# ESP32-H2 register map
Vendor: ESPRESSIF SYSTEMS (SHANGHAI) CO., LTD.; Series: ESP32 H-Series; File version: 12
CPU: RV32IMAC r0p0, little endian, no MPU, no FPU, 0 interrupt priority bits
Address unit: 32 bits
Registers are 32-bit, read-write, reset 0x0 unless marked. A register's access mark holds for its fields unless they carry their own. Offsets are from the block's base; [hi:lo] are bit positions; {n}, {i} and the like mark numbered series.

## GPIO — General Purpose Input/Output
Base 0x60091000
0x00 BT_SELECT — GPIO bit select register
  [31:0] BT_SEL
0x04 OUT — GPIO output register for GPIO0-31
  [31:0] DATA_ORIG
0x08 OUT_W1TS wo — GPIO output set register for GPIO0-31
0x0C OUT_W1TC wo — GPIO output clear register for GPIO0-31
0x1C SDIO_SELECT — GPIO sdio select register
  [7:0] SDIO_SEL
0x20 ENABLE — GPIO output enable register for GPIO0-31
  [31:0] DATA
0x24 ENABLE_W1TS wo — GPIO output enable set register for GPIO0-31
0x28 ENABLE_W1TC wo — GPIO output enable clear register for GPIO0-31
0x38 STRAP ro — pad strapping register
  [15:0] STRAPPING
0x3C IN ro — GPIO input register for GPIO0-31
  [31:0] DATA_NEXT
0x44 STATUS — GPIO interrupt status register for GPIO0-31
  [31:0] INTERRUPT
0x48 STATUS_W1TS wo — GPIO interrupt status set register for GPIO0-31
0x4C STATUS_W1TC wo — GPIO interrupt status clear register for GPIO0-31
0x5C PCPU_INT ro — GPIO PRO_CPU interrupt status register for GPIO0-31
  [31:0] PROCPU_INT
0x60 PCPU_NMI_INT ro — GPIO PRO_CPU(not shielded) interrupt status register for GPIO0-31
  [31:0] PROCPU_NMI_INT
0x64 CPUSDIO_INT ro — GPIO CPUSDIO interrupt status register for GPIO0-31
  [31:0] SDIO_INT
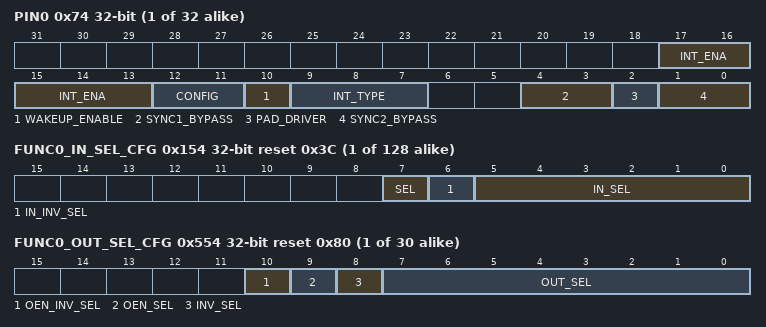
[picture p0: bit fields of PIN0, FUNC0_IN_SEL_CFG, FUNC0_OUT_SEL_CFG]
{0x74+4i} PIN{i} (i=0..31) — GPIO pin configuration register
  [17:13] INT_ENA — set bit 13 to enable CPU interrupt. set bit 14 to enable CPU(not shielded) interrupt.
  [12:11] CONFIG — reserved
  [10] WAKEUP_ENABLE — set this bit to enable GPIO wakeup.(can only wakeup CPU from Light-sleep Mode)
  [9:7] INT_TYPE — set this value to choose interrupt mode. 0:disable GPIO interrupt. 1:trigger at posedge. 2:trigger at negedge. 3:trigger at any edge. 4:valid at low level. 5:valid at high level
  [4:3] SYNC1_BYPASS — set GPIO input_sync1 signal mode. 0:disable. 1:trigger at negedge. 2or3:trigger at posedge.
  [2] PAD_DRIVER — set this bit to select pad driver. 1:open-drain. 0:normal.
  [1:0] SYNC2_BYPASS — set GPIO input_sync2 signal mode. 0:disable. 1:trigger at negedge. 2or3:trigger at posedge.
0x14C STATUS_NEXT ro — GPIO interrupt source register for GPIO0-31
  [31:0] STATUS_INTERRUPT_NEXT
{0x154+4i} FUNC{i}_IN_SEL_CFG (i=0..127) reset 0x3C — GPIO input function configuration register
  [7] SEL — set this bit to bypass GPIO. 1:do not bypass GPIO. 0:bypass GPIO.
  [6] IN_INV_SEL — set this bit to invert input signal. 1:invert. 0:not invert.
  [5:0] IN_SEL — set this value: s=0-34: connect GPIO[s] to this port. s=0x38: set this port always high level. s=0x3C: set this port always low level.
{0x554+4i} FUNC{i}_OUT_SEL_CFG (i=0..29) reset 0x80 — GPIO output function select register
  [10] OEN_INV_SEL — set this bit to invert output enable signal.1:invert.0:not invert.
  [9] OEN_SEL — set this bit to select output enable signal.1:use GPIO_ENABLE_REG[n] as output enable signal.0:use peripheral output enable signal.
  [8] INV_SEL — set this bit to invert output signal.1:invert.0:not invert.
  [7:0] OUT_SEL — The value of the bits: 0<=s<=256. Set the value to select output signal. s=0-127: output of GPIO[n] equals input of peripheral[s]. s=128: output of GPIO[n] equals GPIO_OUT_REG[n].
0x62C CLOCK_GATE reset 0x1 — GPIO clock gate register
  [0] CLK_EN — set this bit to enable GPIO clock gate
0x6FC DATE — GPIO version register

## GPIO_SD — Sigma-Delta Modulation
Base 0x60091F00
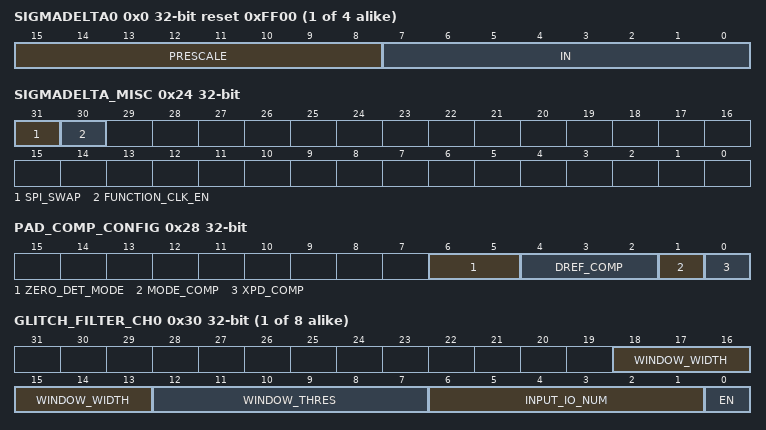
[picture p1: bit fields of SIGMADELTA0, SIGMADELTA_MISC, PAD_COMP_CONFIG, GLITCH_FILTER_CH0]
{0x0+4i} SIGMADELTA{i} (i=0..3) reset 0xFF00 — Duty Cycle Configure Register of SDM{i}
  [15:8] PRESCALE — This field is used to set a divider value to divide APB clock.
  [7:0] IN — This field is used to configure the duty cycle of sigma delta modulation output.
0x20 CLOCK_GATE — Clock Gating Configure Register
  [0] CLK_EN — Clock enable bit of configuration registers for sigma delta modulation.
0x24 SIGMADELTA_MISC — MISC Register
  [31] SPI_SWAP — Reserved.
  [30] FUNCTION_CLK_EN — Clock enable bit of sigma delta modulation.
0x28 PAD_COMP_CONFIG — PAD Compare configure Register
  [6:5] ZERO_DET_MODE — Zero Detect mode select.
  [4:2] DREF_COMP — internal reference voltage tuning bit. 0V to 0.7*VDDPST step 0.1*VDDPST.
  [1] MODE_COMP — 1 to enable external reference from PAD[0]. 0 to enable internal reference, meanwhile PAD[0] can be used as a regular GPIO.
  [0] XPD_COMP — Pad compare enable bit.
0x2C PAD_COMP_FILTER — Zero Detect filter Register
  [31:0] ZERO_DET_FILTER_CNT — Zero Detect filter cycle length
{0x30+4i} GLITCH_FILTER_CH{i} (i=0..7) — Glitch Filter Configure Register of Channel{i}
  [18:13] WINDOW_WIDTH — Glitch Filter window width.
  [12:7] WINDOW_THRES — Glitch Filter window threshold.
  [6:1] INPUT_IO_NUM — Glitch Filter input io number.
  [0] EN — Glitch Filter channel enable bit.
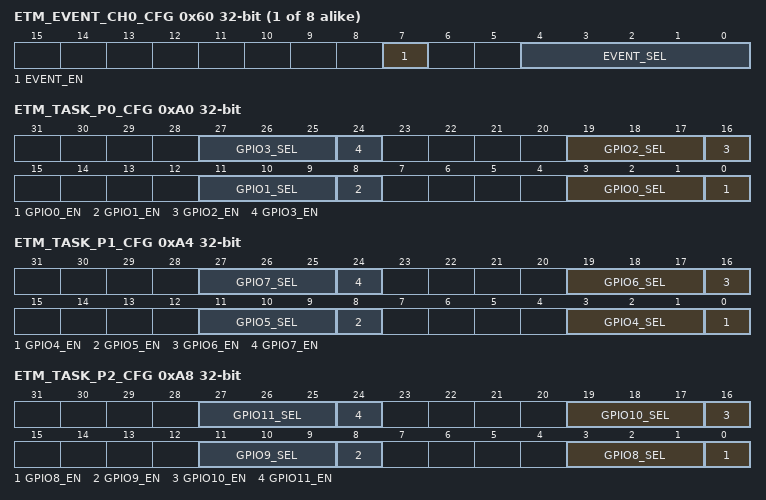
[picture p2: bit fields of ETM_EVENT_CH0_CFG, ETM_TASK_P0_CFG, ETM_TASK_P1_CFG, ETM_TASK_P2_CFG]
{0x60+4i} ETM_EVENT_CH{i}_CFG (i=0..7) — Etm Config register of Channel{i}
  [7] EVENT_EN — Etm event send enable bit.
  [4:0] EVENT_SEL — Etm event channel select gpio.
0xA0 ETM_TASK_P0_CFG — Etm Configure Register to decide which GPIO been chosen
  [8n+3:8n+1] GPIO{n}_SEL (n=0..3) — GPIO choose a etm task channel.
  [8n] GPIO{n}_EN (n=0..3) — Enable bit of GPIO response etm task.
0xA4 ETM_TASK_P1_CFG — Etm Configure Register to decide which GPIO been chosen
  [8n-29:8n-31] GPIO{n}_SEL (n=4..7) — GPIO choose a etm task channel.
  [8n-32] GPIO{n}_EN (n=4..7) — Enable bit of GPIO response etm task.
0xA8 ETM_TASK_P2_CFG — Etm Configure Register to decide which GPIO been chosen
  [8n-61:8n-63] GPIO{n}_SEL (n=8..11) — GPIO choose a etm task channel.
  [8n-64] GPIO{n}_EN (n=8..11) — Enable bit of GPIO response etm task.
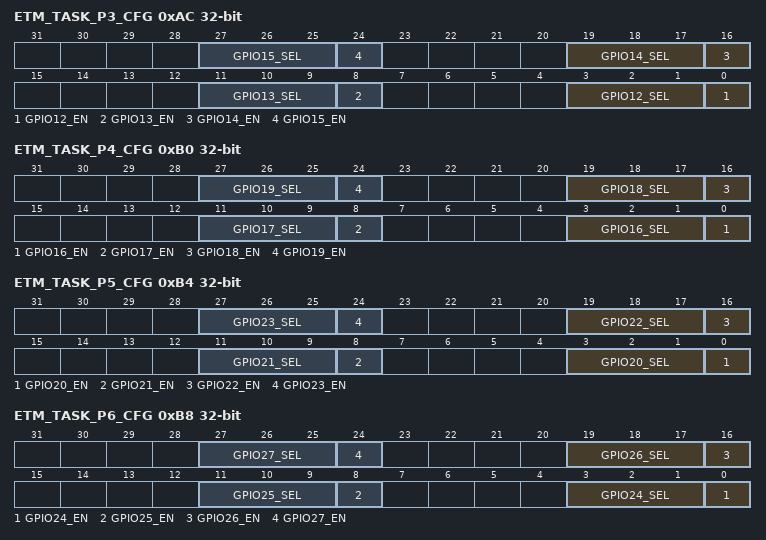
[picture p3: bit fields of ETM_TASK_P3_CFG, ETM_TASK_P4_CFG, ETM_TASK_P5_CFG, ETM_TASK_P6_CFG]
0xAC ETM_TASK_P3_CFG — Etm Configure Register to decide which GPIO been chosen
  [8n-93:8n-95] GPIO{n}_SEL (n=12..15) — GPIO choose a etm task channel.
  [8n-96] GPIO{n}_EN (n=12..15) — Enable bit of GPIO response etm task.
0xB0 ETM_TASK_P4_CFG — Etm Configure Register to decide which GPIO been chosen
  [8n-125:8n-127] GPIO{n}_SEL (n=16..19) — GPIO choose a etm task channel.
  [8n-128] GPIO{n}_EN (n=16..19) — Enable bit of GPIO response etm task.
0xB4 ETM_TASK_P5_CFG — Etm Configure Register to decide which GPIO been chosen
  [8n-157:8n-159] GPIO{n}_SEL (n=20..23) — GPIO choose a etm task channel.
  [8n-160] GPIO{n}_EN (n=20..23) — Enable bit of GPIO response etm task.
0xB8 ETM_TASK_P6_CFG — Etm Configure Register to decide which GPIO been chosen
  [8n-189:8n-191] GPIO{n}_SEL (n=24..27) — GPIO choose a etm task channel.
  [8n-192] GPIO{n}_EN (n=24..27) — Enable bit of GPIO response etm task.
0xE0 INT_RAW ro — GPIOSD interrupt raw register
  [0] PAD_COMP — Pad compare raw interrupt
0xE4 INT_ST ro — GPIOSD interrupt masked register
  [0] PAD_COMP — Pad compare masked interrupt
0xE8 INT_ENA — GPIOSD interrupt enable register
  [0] PAD_COMP — Pad compare interrupt enable
0xEC INT_CLR wo — GPIOSD interrupt clear register
  [0] PAD_COMP write-1-clears — Pad compare interrupt clear
0xFC VERSION — Version Control Register
